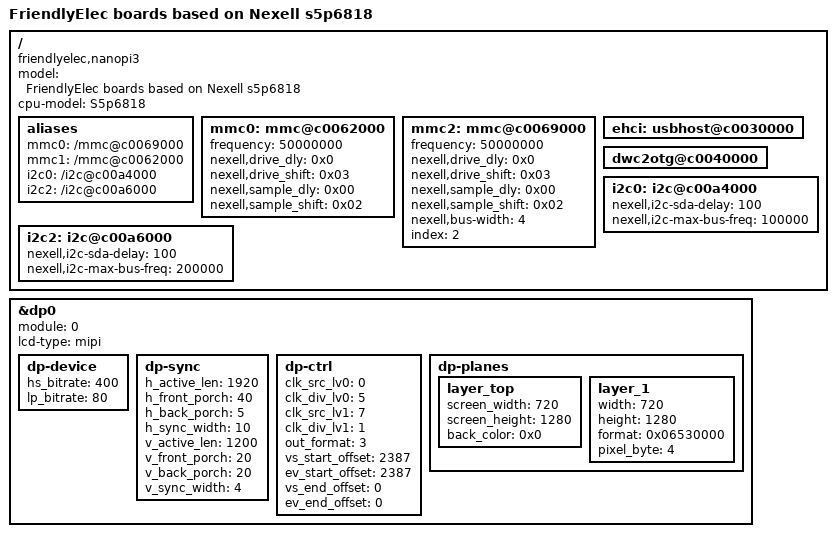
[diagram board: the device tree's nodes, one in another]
/*
 * (C) Copyright 2017 FriendlyElec Computer Tech. Co., Ltd.
 * (http://www.friendlyarm.com)
 *
 * (C) Copyright 2016 Nexell
 * Youngbok, Park <park@nexell.co.kr>
 *
 * SPDX-License-Identifier:      GPL-2.0+
 */

/dts-v1/;
#include "s5p6818.dtsi"

/ {
	model = "FriendlyElec boards based on Nexell s5p6818";
	cpu-model = "S5p6818";

	compatible = "friendlyelec,nanopi3",
		   "nexell,s5p6818";

	aliases {
		mmc0 = "/mmc@c0069000";
		mmc1 = "/mmc@c0062000";
		i2c0 = "/i2c@c00a4000";
		i2c2 = "/i2c@c00a6000";
	};

	mmc0:mmc@c0062000 {
		frequency = <50000000>;
		nexell,drive_dly = <0x0>;
		nexell,drive_shift = <0x03>;
		nexell,sample_dly = <0x00>;
		nexell,sample_shift = <0x02>;
		status = "okay";
	};

	mmc2:mmc@c0069000 {
		frequency = <50000000>;
		nexell,drive_dly = <0x0>;
		nexell,drive_shift = <0x03>;
		nexell,sample_dly = <0x00>;
		nexell,sample_shift = <0x02>;
		nexell,bus-width = <4>;
		index = <2>;
		status = "okay";
	};

	ehci:usbhost@c0030000 {
		status = "okay";
	};

	dwc2otg@c0040000 {
		status = "okay";
	};

	i2c0:i2c@c00a4000 {
		status ="okay";
		nexell,i2c-sda-delay = <100>;
		nexell,i2c-max-bus-freq = <100000>;
	};

	i2c2:i2c@c00a6000 {
		status ="okay";
		nexell,i2c-sda-delay = <100>;
		nexell,i2c-max-bus-freq = <200000>;
	};
};
&dp0 {
        status = "okay";
        module = <0>;
        lcd-type = "mipi";

	dp-device {
		hs_bitrate = <400>;
		lp_bitrate = <80>;
	};

        dp-sync {
		h_active_len = <1920>;
		h_front_porch = <40>;
		h_back_porch = <5>;
		h_sync_width = <10>;
		v_active_len = <1200>;
		v_front_porch = <20>;
		v_back_porch = <20>;
		v_sync_width = <4>;
	};
	

	dp-ctrl {
		clk_src_lv0 = <0>;
		clk_div_lv0 = <5>;
		clk_src_lv1 = <7>;
		clk_div_lv1 = <1>;
		out_format = <3>;
		vs_start_offset = <2387>;
		ev_start_offset = <2387>;
		vs_end_offset = <0>;
		ev_end_offset = <0>;
	};

	dp-planes {
		layer_top {
			screen_width = <720>;
			screen_height = <1280>;
			back_color = <0x0>;
		};

		layer_1 {	/* RGB 1 */
			width = <720>;
			height = <1280>;
			format = <0x06530000>;
			pixel_byte = <4>;
		};
	};
};


